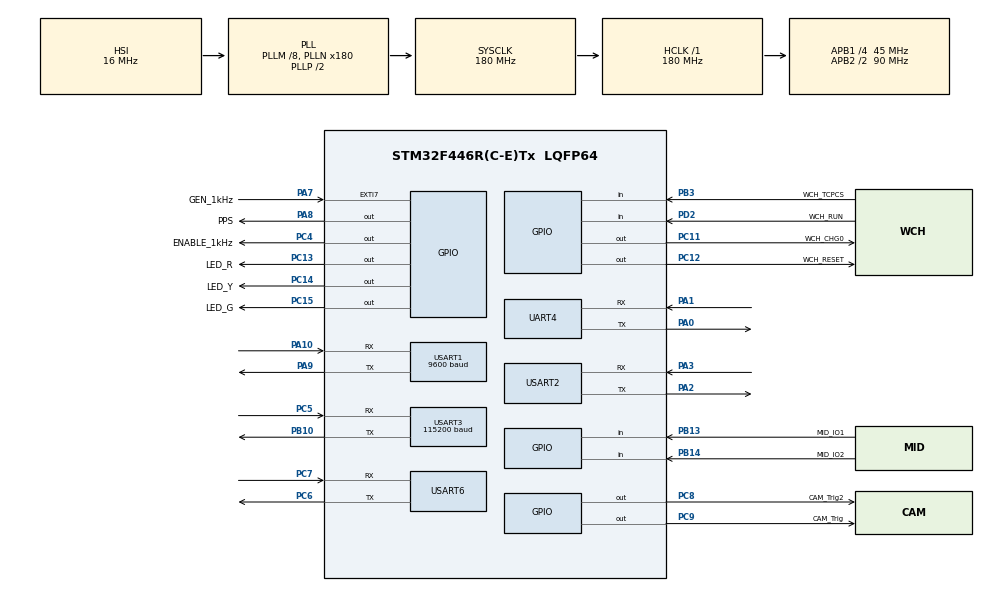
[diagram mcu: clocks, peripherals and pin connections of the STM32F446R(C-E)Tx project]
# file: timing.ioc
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Mcu.Family=STM32F4
Mcu.Name=STM32F446R(C-E)Tx
Mcu.Package=LQFP64
NVIC.EXTI9_5_IRQn=true\:5\:0\:true\:false\:true\:true\:true\:true
NVIC.PriorityGroup=NVIC_PRIORITYGROUP_4
NVIC.UART4_IRQn=true\:7\:0\:true\:false\:true\:true\:true\:true
NVIC.USART1_IRQn=true\:5\:0\:true\:false\:true\:true\:true\:true
NVIC.USART2_IRQn=true\:7\:0\:true\:false\:true\:true\:true\:true
NVIC.USART3_IRQn=true\:7\:0\:true\:false\:true\:true\:true\:true
NVIC.USART6_IRQn=true\:7\:0\:true\:false\:true\:true\:true\:true
PA0-WKUP.Mode=Asynchronous
PA0-WKUP.Signal=UART4_TX
PA1.Mode=Asynchronous
PA1.Signal=UART4_RX
PA10.Mode=Asynchronous
PA10.Signal=USART1_RX
PA13.Mode=Serial_Wire
PA13.Signal=SYS_JTMS-SWDIO
PA14.Mode=Serial_Wire
PA14.Signal=SYS_JTCK-SWCLK
PA2.Mode=Asynchronous
PA2.Signal=USART2_TX
PA3.Mode=Asynchronous
PA3.Signal=USART2_RX
PA7.GPIO_Label=GEN_1kHz
PA7.Signal=GPXTI7
PA8.GPIO_Label=PPS
PA8.Signal=GPIO_Output
PA9.Mode=Asynchronous
PA9.Signal=USART1_TX
PB10.Mode=Asynchronous
PB10.Signal=USART3_TX
PB13.GPIO_Label=MID_IO1
PB13.Signal=GPIO_Input
PB14.GPIO_Label=MID_IO2
PB14.Signal=GPIO_Input
PB3.GPIO_Label=WCH_TCPCS
PB3.Signal=GPIO_Input
PC11.GPIO_Label=WCH_CHG0
PC11.PinState=GPIO_PIN_SET
PC11.Signal=GPIO_Output
PC12.GPIO_Label=WCH_RESET
PC12.PinState=GPIO_PIN_SET
PC12.Signal=GPIO_Output
PC13.GPIO_Label=LED_R
PC13.Signal=GPIO_Output
PC14-OSC32_IN.GPIO_Label=LED_Y
PC14-OSC32_IN.Signal=GPIO_Output
PC15-OSC32_OUT.GPIO_Label=LED_G
PC15-OSC32_OUT.Signal=GPIO_Output
PC4.GPIO_Label=ENABLE_1kHz
PC4.Signal=GPIO_Output
PC5.Mode=Asynchronous
PC5.Signal=USART3_RX
PC6.Mode=Asynchronous
PC6.Signal=USART6_TX
PC7.Mode=Asynchronous
PC7.Signal=USART6_RX
PC8.GPIO_Label=CAM_Trig2
PC8.Signal=GPIO_Output
PC9.GPIO_Label=CAM_Trig
PC9.Signal=GPIO_Output
PD2.GPIO_Label=WCH_RUN
PD2.Signal=GPIO_Input
PH0-OSC_IN.Mode=HSE-External-Oscillator
PH0-OSC_IN.Signal=RCC_OSC_IN
PH1-OSC_OUT.Mode=HSE-External-Oscillator
PH1-OSC_OUT.Signal=RCC_OSC_OUT
ProjectManager.HeapSize=0x200
ProjectManager.StackSize=0x400
ProjectManager.TargetToolchain=STM32CubeIDE
RCC.AHBFreq_Value=180000000
RCC.APB1CLKDivider=RCC_HCLK_DIV4
RCC.APB1Freq_Value=45000000
RCC.APB1TimFreq_Value=90000000
RCC.APB2CLKDivider=RCC_HCLK_DIV2
RCC.APB2Freq_Value=90000000
RCC.APB2TimFreq_Value=180000000
RCC.CortexFreq_Value=180000000
RCC.HCLKFreq_Value=180000000
RCC.HSE_VALUE=8000000
RCC.PLLM=8
RCC.PLLN=180
RCC.SYSCLKFreq_VALUE=180000000
RCC.SYSCLKSource=RCC_SYSCLKSOURCE_PLLCLK
RCC.USBFreq_Value=180000000
RCC.VCOOutputFreq_Value=360000000
UART4.VirtualMode=Asynchronous
USART1.BaudRate=9600
USART1.VirtualMode=VM_ASYNC
USART2.VirtualMode=VM_ASYNC
USART3.BaudRate=115200
USART3.VirtualMode=VM_ASYNC
USART6.VirtualMode=VM_ASYNC
board=custom

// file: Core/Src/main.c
/* USER CODE BEGIN Header */
/**
  ******************************************************************************
  * @file           : main.c
  * @brief          : Main program body
  ******************************************************************************
  * @attention
  *
  * Copyright (c) 2024 STMicroelectronics.
  * All rights reserved.
  *
  * This software is licensed under terms that can be found in the LICENSE file
  * in the root directory of this software component.
  * If no LICENSE file comes with this software, it is provided AS-IS.
  *
  ******************************************************************************
  */
/* USER CODE END Header */
#include "main.h"

/* USER CODE BEGIN Includes */
#include "../Src_timing/trig.h"
/* USER CODE END Includes */

UART_HandleTypeDef huart4;
UART_HandleTypeDef huart1;
UART_HandleTypeDef huart2;
UART_HandleTypeDef huart3;
UART_HandleTypeDef huart6;

void SystemClock_Config(void);
static void MX_GPIO_Init(void);
static void MX_UART4_Init(void);
static void MX_USART1_UART_Init(void);
static void MX_USART2_UART_Init(void);
static void MX_USART3_UART_Init(void);
static void MX_USART6_UART_Init(void);

int main(void)
{

  /* MCU Configuration--------------------------------------------------------*/

  /* Reset of all peripherals, Initializes the Flash interface and the Systick. */
  HAL_Init();

  /* Configure the system clock */
  SystemClock_Config();

  /* Initialize all configured peripherals */
  MX_GPIO_Init();
  MX_UART4_Init();
  MX_USART1_UART_Init();
  MX_USART2_UART_Init();
  MX_USART3_UART_Init();
  MX_USART6_UART_Init();

  /* Infinite loop */
  while (1)
  {

    /* USER CODE BEGIN 3 */
	  foreverLoop();
  }
  /* USER CODE END 3 */
}

void SystemClock_Config(void)
{
  RCC_OscInitTypeDef RCC_OscInitStruct = {0};
  RCC_ClkInitTypeDef RCC_ClkInitStruct = {0};

  /** Configure the main internal regulator output voltage
  */
  __HAL_RCC_PWR_CLK_ENABLE();
  __HAL_PWR_VOLTAGESCALING_CONFIG(PWR_REGULATOR_VOLTAGE_SCALE1);

  /** Initializes the RCC Oscillators according to the specified parameters
  * in the RCC_OscInitTypeDef structure.
  */
  RCC_OscInitStruct.OscillatorType = RCC_OSCILLATORTYPE_HSI;
  RCC_OscInitStruct.HSIState = RCC_HSI_ON;
  RCC_OscInitStruct.HSICalibrationValue = RCC_HSICALIBRATION_DEFAULT;
  RCC_OscInitStruct.PLL.PLLState = RCC_PLL_ON;
  RCC_OscInitStruct.PLL.PLLSource = RCC_PLLSOURCE_HSI;
  RCC_OscInitStruct.PLL.PLLM = 8;
  RCC_OscInitStruct.PLL.PLLN = 180;
  RCC_OscInitStruct.PLL.PLLP = RCC_PLLP_DIV2;
  RCC_OscInitStruct.PLL.PLLQ = 2;
  RCC_OscInitStruct.PLL.PLLR = 2;
  if (HAL_RCC_OscConfig(&RCC_OscInitStruct) != HAL_OK)
  {
    Error_Handler();
  }

  /** Activate the Over-Drive mode
  */
  if (HAL_PWREx_EnableOverDrive() != HAL_OK)
  {
    Error_Handler();
  }

  /** Initializes the CPU, AHB and APB buses clocks
  */
  RCC_ClkInitStruct.ClockType = RCC_CLOCKTYPE_HCLK|RCC_CLOCKTYPE_SYSCLK
                              |RCC_CLOCKTYPE_PCLK1|RCC_CLOCKTYPE_PCLK2;
  RCC_ClkInitStruct.SYSCLKSource = RCC_SYSCLKSOURCE_PLLCLK;
  RCC_ClkInitStruct.AHBCLKDivider = RCC_SYSCLK_DIV1;
  RCC_ClkInitStruct.APB1CLKDivider = RCC_HCLK_DIV4;
  RCC_ClkInitStruct.APB2CLKDivider = RCC_HCLK_DIV2;

  if (HAL_RCC_ClockConfig(&RCC_ClkInitStruct, FLASH_LATENCY_5) != HAL_OK)
  {
    Error_Handler();
  }
}

static void MX_UART4_Init(void)
{

  huart4.Instance = UART4;
  huart4.Init.BaudRate = 115200;
  huart4.Init.WordLength = UART_WORDLENGTH_8B;
  huart4.Init.StopBits = UART_STOPBITS_1;
  huart4.Init.Parity = UART_PARITY_NONE;
  huart4.Init.Mode = UART_MODE_TX_RX;
  huart4.Init.HwFlowCtl = UART_HWCONTROL_NONE;
  huart4.Init.OverSampling = UART_OVERSAMPLING_16;
  if (HAL_UART_Init(&huart4) != HAL_OK)
  {
    Error_Handler();
  }

}

static void MX_USART1_UART_Init(void)
{

  huart1.Instance = USART1;
  huart1.Init.BaudRate = 9600;
  huart1.Init.WordLength = UART_WORDLENGTH_8B;
  huart1.Init.StopBits = UART_STOPBITS_1;
  huart1.Init.Parity = UART_PARITY_NONE;
  huart1.Init.Mode = UART_MODE_TX_RX;
  huart1.Init.HwFlowCtl = UART_HWCONTROL_NONE;
  huart1.Init.OverSampling = UART_OVERSAMPLING_16;
  if (HAL_UART_Init(&huart1) != HAL_OK)
  {
    Error_Handler();
  }

}

static void MX_USART2_UART_Init(void)
{

  huart2.Instance = USART2;
  huart2.Init.BaudRate = 115200;
  huart2.Init.WordLength = UART_WORDLENGTH_8B;
  huart2.Init.StopBits = UART_STOPBITS_1;
  huart2.Init.Parity = UART_PARITY_NONE;
  huart2.Init.Mode = UART_MODE_TX_RX;
  huart2.Init.HwFlowCtl = UART_HWCONTROL_NONE;
  huart2.Init.OverSampling = UART_OVERSAMPLING_16;
  if (HAL_UART_Init(&huart2) != HAL_OK)
  {
    Error_Handler();
  }

}

static void MX_USART3_UART_Init(void)
{

  huart3.Instance = USART3;
  huart3.Init.BaudRate = 115200;
  huart3.Init.WordLength = UART_WORDLENGTH_8B;
  huart3.Init.StopBits = UART_STOPBITS_1;
  huart3.Init.Parity = UART_PARITY_NONE;
  huart3.Init.Mode = UART_MODE_TX_RX;
  huart3.Init.HwFlowCtl = UART_HWCONTROL_NONE;
  huart3.Init.OverSampling = UART_OVERSAMPLING_16;
  if (HAL_UART_Init(&huart3) != HAL_OK)
  {
    Error_Handler();
  }

}

static void MX_USART6_UART_Init(void)
{

  huart6.Instance = USART6;
  huart6.Init.BaudRate = 115200;
  huart6.Init.WordLength = UART_WORDLENGTH_8B;
  huart6.Init.StopBits = UART_STOPBITS_1;
  huart6.Init.Parity = UART_PARITY_NONE;
  huart6.Init.Mode = UART_MODE_TX_RX;
  huart6.Init.HwFlowCtl = UART_HWCONTROL_NONE;
  huart6.Init.OverSampling = UART_OVERSAMPLING_16;
  if (HAL_UART_Init(&huart6) != HAL_OK)
  {
    Error_Handler();
  }

}

static void MX_GPIO_Init(void)
{
  GPIO_InitTypeDef GPIO_InitStruct = {0};

  /* GPIO Ports Clock Enable */
  __HAL_RCC_GPIOC_CLK_ENABLE();
  __HAL_RCC_GPIOH_CLK_ENABLE();
  __HAL_RCC_GPIOA_CLK_ENABLE();
  __HAL_RCC_GPIOB_CLK_ENABLE();
  __HAL_RCC_GPIOD_CLK_ENABLE();

  /*Configure GPIO pin Output Level */
  HAL_GPIO_WritePin(GPIOC, LED_R_Pin|LED_Y_Pin|LED_G_Pin|ENABLE_1kHz_Pin
                          |CAM_Trig2_Pin|CAM_Trig_Pin, GPIO_PIN_RESET);

  /*Configure GPIO pin Output Level */
  HAL_GPIO_WritePin(PPS_GPIO_Port, PPS_Pin, GPIO_PIN_RESET);

  /*Configure GPIO pin Output Level */
  HAL_GPIO_WritePin(GPIOC, WCH_CHG0_Pin|WCH_RESET_Pin, GPIO_PIN_SET);

  /*Configure GPIO pins : LED_R_Pin LED_Y_Pin LED_G_Pin ENABLE_1kHz_Pin
                           CAM_Trig2_Pin CAM_Trig_Pin WCH_CHG0_Pin WCH_RESET_Pin */
  GPIO_InitStruct.Pin = LED_R_Pin|LED_Y_Pin|LED_G_Pin|ENABLE_1kHz_Pin
                          |CAM_Trig2_Pin|CAM_Trig_Pin|WCH_CHG0_Pin|WCH_RESET_Pin;
  GPIO_InitStruct.Mode = GPIO_MODE_OUTPUT_PP;
  GPIO_InitStruct.Pull = GPIO_NOPULL;
  GPIO_InitStruct.Speed = GPIO_SPEED_FREQ_LOW;
  HAL_GPIO_Init(GPIOC, &GPIO_InitStruct);

  /*Configure GPIO pin : GEN_1kHz_Pin */
  GPIO_InitStruct.Pin = GEN_1kHz_Pin;
  GPIO_InitStruct.Mode = GPIO_MODE_IT_RISING;
  GPIO_InitStruct.Pull = GPIO_NOPULL;
  HAL_GPIO_Init(GEN_1kHz_GPIO_Port, &GPIO_InitStruct);

  /*Configure GPIO pins : MID_IO1_Pin MID_IO2_Pin WCH_TCPCS_Pin */
  GPIO_InitStruct.Pin = MID_IO1_Pin|MID_IO2_Pin|WCH_TCPCS_Pin;
  GPIO_InitStruct.Mode = GPIO_MODE_INPUT;
  GPIO_InitStruct.Pull = GPIO_NOPULL;
  HAL_GPIO_Init(GPIOB, &GPIO_InitStruct);

  /*Configure GPIO pin : PPS_Pin */
  GPIO_InitStruct.Pin = PPS_Pin;
  GPIO_InitStruct.Mode = GPIO_MODE_OUTPUT_PP;
  GPIO_InitStruct.Pull = GPIO_NOPULL;
  GPIO_InitStruct.Speed = GPIO_SPEED_FREQ_LOW;
  HAL_GPIO_Init(PPS_GPIO_Port, &GPIO_InitStruct);

  /*Configure GPIO pin : WCH_RUN_Pin */
  GPIO_InitStruct.Pin = WCH_RUN_Pin;
  GPIO_InitStruct.Mode = GPIO_MODE_INPUT;
  GPIO_InitStruct.Pull = GPIO_NOPULL;
  HAL_GPIO_Init(WCH_RUN_GPIO_Port, &GPIO_InitStruct);

  /* EXTI interrupt init*/
  HAL_NVIC_SetPriority(EXTI9_5_IRQn, 5, 0);
  HAL_NVIC_EnableIRQ(EXTI9_5_IRQn);

}

void Error_Handler(void)
{
  __disable_irq();
  while (1)
  {
  }
}
